AUTOSAR XML (schema 4-0-3)
package /ComponentTypes
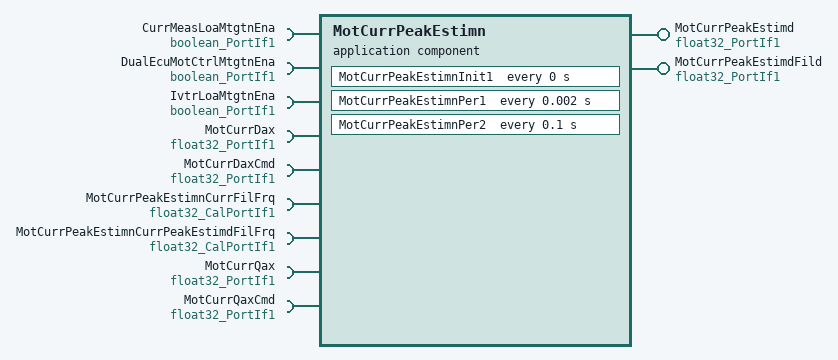
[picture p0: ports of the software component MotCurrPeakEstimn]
  application sw component type MotCurrPeakEstimn
    provide port MotCurrPeakEstimd: nonqueued-sender-com-spec{data-element=Val, init-value=0}, provided-interface=float32_PortIf1
    provide port MotCurrPeakEstimdFild: nonqueued-sender-com-spec{data-element=Val, init-value=0}, provided-interface=float32_PortIf1
    9 x require port:
      CurrMeasLoaMtgtnEna: nonqueued-receiver-com-spec{data-element=Logl, filter=data-filter-type=ALWAYS, init-value=0}, required-interface=boolean_PortIf1
      DualEcuMotCtrlMtgtnEna: nonqueued-receiver-com-spec{data-element=Logl, filter=data-filter-type=ALWAYS, init-value=0}, required-interface=boolean_PortIf1
      IvtrLoaMtgtnEna: nonqueued-receiver-com-spec{data-element=Logl, filter=data-filter-type=ALWAYS, init-value=0}, required-interface=boolean_PortIf1
      MotCurrDax: nonqueued-receiver-com-spec{data-element=Val, filter=data-filter-type=ALWAYS, init-value=0}, required-interface=float32_PortIf1
      MotCurrDaxCmd: nonqueued-receiver-com-spec{data-element=Val, filter=data-filter-type=ALWAYS, init-value=0}, required-interface=float32_PortIf1
      MotCurrPeakEstimnCurrFilFrq: parameter-require-com-spec{init-value=8, parameter=Val}, required-interface=float32_CalPortIf1
      MotCurrPeakEstimnCurrPeakEstimdFilFrq: parameter-require-com-spec{init-value=0.03, parameter=Val}, required-interface=float32_CalPortIf1
      MotCurrQax: nonqueued-receiver-com-spec{data-element=Val, filter=data-filter-type=ALWAYS, init-value=0}, required-interface=float32_PortIf1
      MotCurrQaxCmd: nonqueued-receiver-com-spec{data-element=Val, filter=data-filter-type=ALWAYS, init-value=0}, required-interface=float32_PortIf1
    behavior MotCurrPeakEstimn_InternalBehavior
      ar-typed-per-instance-memorys:
        5 x data, all with sw-calibration-access=READ-ONLY:
          dMotCurrPeakEstimnMotCurrDaxFil: type=float32
          dMotCurrPeakEstimnMotCurrQaxFil: type=float32
          MotCurrDaxFil: type=FilLpRec1
          MotCurrPeakEstimdFil: type=FilLpRec1
          MotCurrQaxFil: type=FilLpRec1
      timing event MotCurrPeakEstimn_InitEvent: start-on-event=MotCurrPeakEstimnInit1, period=0
      timing event TMT_MotCurrPeakEstimnPer1: start-on-event=MotCurrPeakEstimnPer1, period=0.002
      timing event TMT_MotCurrPeakEstimnPer2: start-on-event=MotCurrPeakEstimnPer2, period=0.1
      explicit-inter-runnable-variables:
        data MotCurrEstimd: type=float32, init-value=0
      runnable MotCurrPeakEstimnInit1
      runnable MotCurrPeakEstimnPer1
        data-receive-point-by-arguments:
          7 x access:
            REC_DualEcuMotCtrlMtgtnEna_Logl: accessed-variable=DualEcuMotCtrlMtgtnEna.Logl
            REC_IvtrLoaMtgtnEna_Logl: accessed-variable=IvtrLoaMtgtnEna.Logl
            REC_MotCurrDax_Val: accessed-variable=MotCurrDax.Val
            REC_MotCurrDaxCmd_Val: accessed-variable=MotCurrDaxCmd.Val
            REC_MotCurrLoaMtgtnEna_Logl: accessed-variable=CurrMeasLoaMtgtnEna.Logl
            REC_MotCurrQax_Val: accessed-variable=MotCurrQax.Val
            REC_MotCurrQaxCmd_Val: accessed-variable=MotCurrQaxCmd.Val
        data-send-points:
          access SEND_MotCurrPeakEstimd_Val: accessed-variable=MotCurrPeakEstimd.Val
        written-local-variables:
          access WRITE_MotCurrEstimd: accessed-variable=MotCurrEstimd
      runnable MotCurrPeakEstimnPer2
        data-send-points:
          access SEND_MotCurrPeakEstimdFild_Val: accessed-variable=MotCurrPeakEstimdFild.Val
        read-local-variables:
          access READ_MotCurrEstimd: accessed-variable=MotCurrEstimd
  swc implementation MotCurrPeakEstimn_Implementation: behavior=MotCurrPeakEstimn_InternalBehavior
    code-descriptors:
      code Default: artifact-descriptors=autosar-engineering-object={short-label=Default, category=SWSRC}
